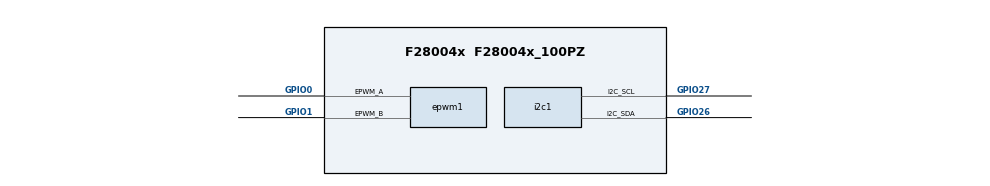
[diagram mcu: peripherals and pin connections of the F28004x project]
/**
 * @cliArgs --device "F28004x" --part "F28004x_100PZ" --package "F28004x_100PZ" --context "system" --product "C2000WARE@26.01.00.00"
 * @versions {"tool":"1.27.0+4565"}
 */

/**
 * Import the modules used in this configuration.
 */
const adc         = scripting.addModule("/driverlib/adc.js", {}, false);
const adc1        = adc.addInstance();
const asysctl     = scripting.addModule("/driverlib/asysctl.js");
const cputimer    = scripting.addModule("/driverlib/cputimer.js", {}, false);
const cputimer1   = cputimer.addInstance();
const epwm        = scripting.addModule("/driverlib/epwm.js", {}, false);
const epwm1       = epwm.addInstance();
const i2c         = scripting.addModule("/driverlib/i2c.js", {}, false);
const i2c1        = i2c.addInstance();
const controller  = scripting.addModule("/libraries/control/dcl/controller.js", {}, false);
const controller1 = controller.addInstance();
const FPUfastRTS  = scripting.addModule("/libraries/math/FPUfastRTS/FPUfastRTS.js", {}, false);
const FPUfastRTS1 = FPUfastRTS.addInstance();

/**
 * Write custom configuration values to the imported modules.
 */
adc1.adcClockPrescaler              = "ADC_CLK_DIV_4_0";
adc1.socHighPriorityMode            = "ADC_PRI_ALL_HIPRI";
adc1.$name                          = "A0";
adc1.soc0SampleWindow               = 10;
adc1.soc0Trigger                    = "ADC_TRIGGER_EPWM1_SOCA";
adc1.interruptPulseMode             = "ADC_PULSE_END_OF_CONV";
adc1.enabledInts                    = ["ADC_INT_NUMBER1"];
adc1.enableInterrupt1               = true;
adc1.enableInterrupt1ContinuousMode = true;
adc1.registerInterrupts             = ["1"];
adc1.enabledSOCs                    = ["ADC_SOC_NUMBER0","ADC_SOC_NUMBER1"];
adc1.soc1SampleWindow               = 10;
adc1.soc1Trigger                    = "ADC_TRIGGER_EPWM1_SOCA";
adc1.soc0Channel                    = "ADC_CH_ADCIN1";
adc1.soc1Channel                    = "ADC_CH_ADCIN2";
adc1.adcInt1.enableInterrupt        = true;

asysctl.analogReference        = "INTERNAL";
asysctl.analogReferenceVoltage = "1P65";

cputimer1.$name                    = "myCPUTIMER0";
cputimer1.timerPeriod              = 999999;
cputimer1.enableInterrupt          = true;
cputimer1.registerInterrupts       = true;
cputimer1.startTimer               = true;
cputimer1.timerInt.enableInterrupt = true;

const default_warning = scripting.addModule("/driverlib/default_warning.js", {}, false);
scripting.suppress("Add the \'Device Support\' module in order to use Clock Tree tool and generate device support files\\. This suggestion can be ignored if not using the Clock Tree tool\\.", default_warning);

epwm1.$name                                                      = "EPWMA";
epwm1.epwmTimebase_hsClockDiv                                    = "EPWM_HSCLOCK_DIVIDER_1";
epwm1.epwmTimebase_counterMode                                   = "EPWM_COUNTER_MODE_UP_DOWN";
epwm1.epwmTimebase_syncOutPulseMode                              = "EPWM_SYNC_OUT_PULSE_ON_COUNTER_ZERO";
epwm1.epwmTimebase_forceSyncPulse                                = true;
epwm1.epwmCounterCompare_cmpA                                    = 1250;
epwm1.epwmDeadband_polarityFED                                   = "EPWM_DB_POLARITY_ACTIVE_LOW";
epwm1.epwmDeadband_enableRED                                     = true;
epwm1.epwmDeadband_delayRED                                      = 20;
epwm1.epwmDeadband_enableFED                                     = true;
epwm1.epwmDeadband_delayFED                                      = 20;
epwm1.epwmEventTrigger_enableInterrupt                           = true;
epwm1.epwmEventTrigger_registerInterrupts                        = true;
epwm1.epwmEventTrigger_interruptSource                           = "EPWM_INT_TBCTR_PERIOD";
epwm1.epwmEventTrigger_interruptEventCount                       = "1";
epwm1.epwmActionQualifier_EPWM_AQ_OUTPUT_A_shadowMode            = true;
epwm1.epwmActionQualifier_EPWM_AQ_OUTPUT_B_shadowMode            = true;
epwm1.epwmActionQualifier_EPWM_AQ_OUTPUT_A_ON_TIMEBASE_UP_CMPA   = "EPWM_AQ_OUTPUT_LOW";
epwm1.epwmActionQualifier_EPWM_AQ_OUTPUT_A_ON_TIMEBASE_DOWN_CMPA = "EPWM_AQ_OUTPUT_HIGH";
epwm1.epwmActionQualifier_EPWM_AQ_OUTPUT_B_ON_TIMEBASE_UP_CMPA   = "EPWM_AQ_OUTPUT_LOW";
epwm1.epwmActionQualifier_EPWM_AQ_OUTPUT_B_ON_TIMEBASE_DOWN_CMPA = "EPWM_AQ_OUTPUT_HIGH";
epwm1.epwmEventTrigger_EPWM_SOC_A_triggerEnable                  = true;
epwm1.epwmEventTrigger_EPWM_SOC_A_triggerSource                  = "EPWM_SOC_TBCTR_ZERO";
epwm1.epwmEventTrigger_EPWM_SOC_A_triggerEventPrescalar          = "1";
epwm1.epwmCounterCompare_cmpB                                    = 1250;
epwm1.epwmTimebase_period                                        = 2500;
epwm1.epwmTripZone_EPWM_TZ_ACTION_EVENT_TZA                      = "EPWM_TZ_ACTION_LOW";
epwm1.epwmTripZone_EPWM_TZ_ACTION_EVENT_TZB                      = "EPWM_TZ_ACTION_LOW";
epwm1.epwm.$assign                                               = "EPWM1";
epwm1.epwm.epwm_aPin.$assign                                     = "GPIO0";
epwm1.epwm.epwm_bPin.$assign                                     = "GPIO1";
epwm1.epwmInt.enableInterrupt                                    = true;

i2c1.$name                  = "myI2C0";
i2c1.useInterfacePins       = ["I2C@_SCL","I2C@_SDA"];
i2c1.dataCount              = 2;
i2c1.bitCount               = "I2C_BITCOUNT_8";
i2c1.i2c.i2c_sdaPin.$assign = "GPIO26";
i2c1.i2c.i2c_sclPin.$assign = "GPIO27";

controller1.$name            = "myPID_Uout";
controller1.controllerChoice = "PI";
controller1.Umin             = "0.0f";
controller1.Imin             = "0";
controller1.Ki               = "0.0001f";
controller1.Kp               = "0.012f";

FPUfastRTS1.$name = "myFFR0";

/**
 * Pinmux solution for unlocked pins/peripherals. This ensures that minor changes to the automatic solver in a future
 * version of the tool will not impact the pinmux you originally saw.  These lines can be completely deleted in order to
 * re-solve from scratch.
 */
i2c1.i2c.$suggestSolution = "I2CA";
